# STM32G483VET6 register map
File version: 1.0
Registers are 32-bit, access not given, reset 0x0 unless marked. A register's access mark holds for its fields unless they carry their own. Offsets are from the block's base; [hi:lo] are bit positions; {n}, {i} and the like mark numbered series.

## DMAMUX1
Base 0x40020800
0x00 CCR0
0x04 CCR1
0x08 CCR2
0x0C CCR3
0x10 CCR4
0x14 CCR5
{0x0+4i} CCR{i} (i=6..9)
0x28 CCR0
0x2C CCR1
0x30 CCR2
0x34 CCR3
0x38 CCR4
0x3C CCR5
0x80 CCRs
0x100 CCR0
0x104 CCR1
0x108 CCR2
0x10C CCR3
0x140 CCRs

## CORDIC
Base 0x40020C00
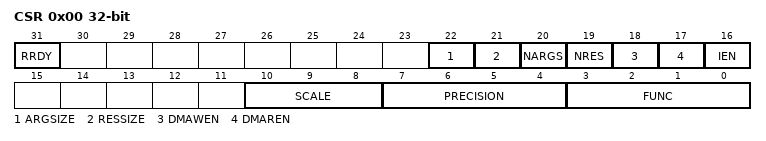
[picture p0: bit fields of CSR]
0x00 CSR
  [31] RRDY, [22] ARGSIZE, [21] RESSIZE, [20] NARGS, [19] NRES, [18] DMAWEN, [17] DMAREN, [16] IEN, [10:8] SCALE, [7:4] PRECISION, [3:0] FUNC
0x04 WDATA
  [31:0] ARG
0x08 RDATA
  [31:0] RES

## FMAC
Base 0x40021400
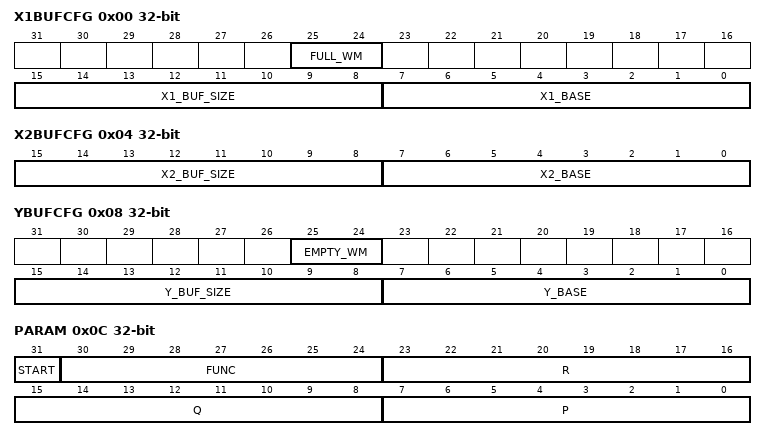
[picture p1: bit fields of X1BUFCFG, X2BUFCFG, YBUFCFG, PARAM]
0x00 X1BUFCFG
  [25:24] FULL_WM, [15:8] X1_BUF_SIZE, [7:0] X1_BASE
0x04 X2BUFCFG
  [15:8] X2_BUF_SIZE, [7:0] X2_BASE
0x08 YBUFCFG
  [25:24] EMPTY_WM, [15:8] Y_BUF_SIZE, [7:0] Y_BASE
0x0C PARAM
  [31] START, [30:24] FUNC, [23:16] R, [15:8] Q, [7:0] P
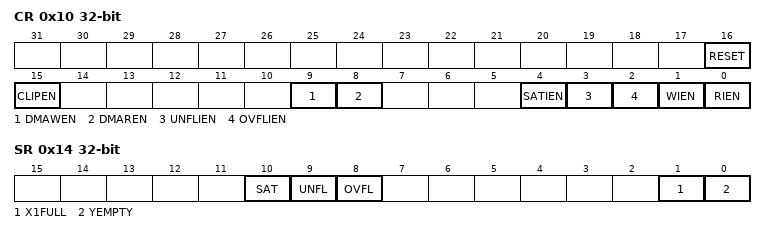
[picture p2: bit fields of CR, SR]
0x10 CR
  [16] RESET, [15] CLIPEN, [9] DMAWEN, [8] DMAREN, [4] SATIEN, [3] UNFLIEN, [2] OVFLIEN, [1] WIEN, [0] RIEN
0x14 SR
  [10] SAT, [9] UNFL, [8] OVFL, [1] X1FULL, [0] YEMPTY
0x18 WDATA
  [15:0] WDATA
0x1C RDATA
  [15:0] RDATA

## FLASH
Base 0x40022000
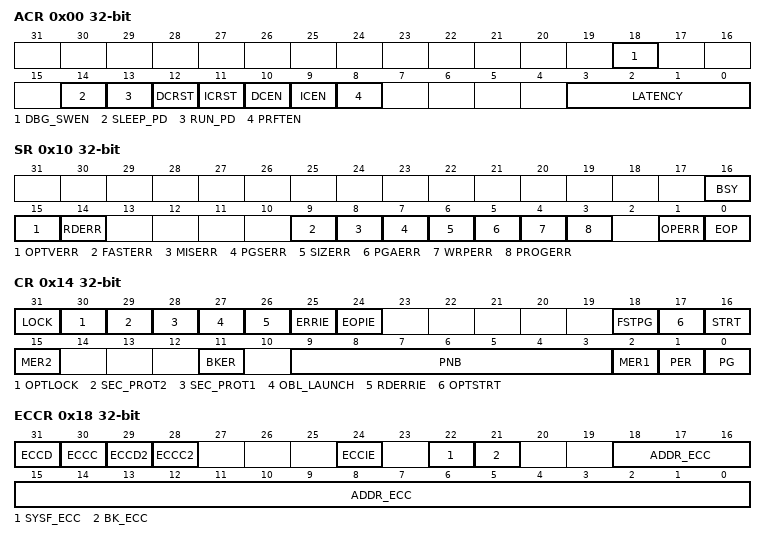
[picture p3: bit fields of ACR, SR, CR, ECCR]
0x00 ACR
  [18] DBG_SWEN, [14] SLEEP_PD, [13] RUN_PD, [12] DCRST, [11] ICRST, [10] DCEN, [9] ICEN, [8] PRFTEN, [3:0] LATENCY
0x04 PDKEYR
0x08 KEYR
0x0C OPTKEYR
0x10 SR
  [16] BSY, [15] OPTVERR, [14] RDERR, [9] FASTERR, [8] MISERR, [7] PGSERR, [6] SIZERR, [5] PGAERR, [4] WRPERR, [3] PROGERR, [1] OPERR, [0] EOP
0x14 CR
  [31] LOCK, [30] OPTLOCK, [29] SEC_PROT2, [28] SEC_PROT1, [27] OBL_LAUNCH, [26] RDERRIE, [25] ERRIE, [24] EOPIE, [18] FSTPG, [17] OPTSTRT, [16] STRT, [15] MER2, [11] BKER, [9:3] PNB, [2] MER1, [1] PER, [0] PG
0x18 ECCR
  [31] ECCD, [30] ECCC, [29] ECCD2, [28] ECCC2, [24] ECCIE, [22] SYSF_ECC, [21] BK_ECC, [18:0] ADDR_ECC
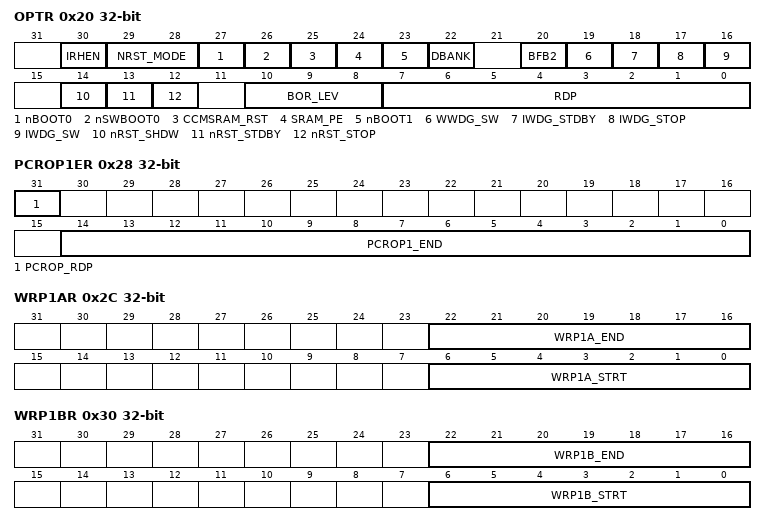
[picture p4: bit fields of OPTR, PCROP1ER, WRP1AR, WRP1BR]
0x20 OPTR
  [30] IRHEN, [29:28] NRST_MODE, [27] nBOOT0, [26] nSWBOOT0, [25] CCMSRAM_RST, [24] SRAM_PE, [23] nBOOT1, [22] DBANK, [20] BFB2, [19] WWDG_SW, [18] IWDG_STDBY, [17] IWDG_STOP, [16] IWDG_SW, [14] nRST_SHDW, [13] nRST_STDBY, [12] nRST_STOP, [10:8] BOR_LEV, [7:0] RDP
0x24 PCROP1SR
  [14:0] PCROP1_STRT
0x28 PCROP1ER
  [31] PCROP_RDP, [14:0] PCROP1_END
0x2C WRP1AR
  [22:16] WRP1A_END, [6:0] WRP1A_STRT
0x30 WRP1BR
  [22:16] WRP1B_END, [6:0] WRP1B_STRT
0x44 PCROP2SR
  [14:0] PCROP2_STRT
0x48 PCROP2ER
  [14:0] PCROP2_END
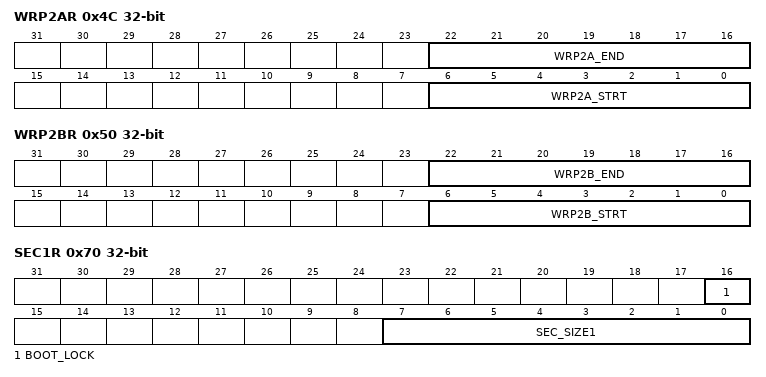
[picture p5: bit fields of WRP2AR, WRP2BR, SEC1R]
0x4C WRP2AR
  [22:16] WRP2A_END, [6:0] WRP2A_STRT
0x50 WRP2BR
  [22:16] WRP2B_END, [6:0] WRP2B_STRT
0x70 SEC1R
  [16] BOOT_LOCK, [7:0] SEC_SIZE1
0x74 SEC2R
  [7:0] SEC_SIZE2

## CRC
Base 0x40023000
0x00 DR
0x04 IDR
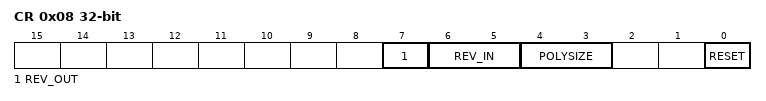
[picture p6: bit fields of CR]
0x08 CR
  [7] REV_OUT, [6:5] REV_IN, [4:3] POLYSIZE, [0] RESET
0x10 INIT
0x14 POL

## GPIOA
Base 0x48000000
Same registers: GPIOB 0x48000400, GPIOC 0x48000800, GPIOD 0x48000C00, GPIOE 0x48001000, GPIOF 0x48001400, GPIOG 0x48001800
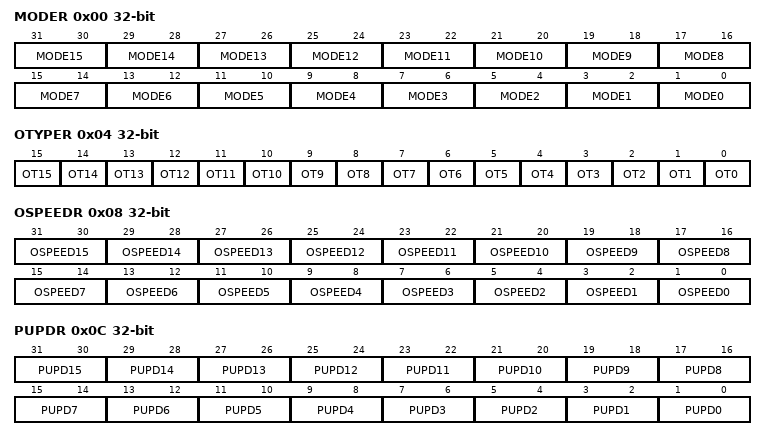
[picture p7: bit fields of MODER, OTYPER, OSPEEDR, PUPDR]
0x00 MODER
  [2n+1:2n] MODE{n} (n=0..15)
0x04 OTYPER
  [n] OT{n} (n=0..15)
0x08 OSPEEDR
  [2n+1:2n] OSPEED{n} (n=0..15)
0x0C PUPDR
  [2n+1:2n] PUPD{n} (n=0..15)
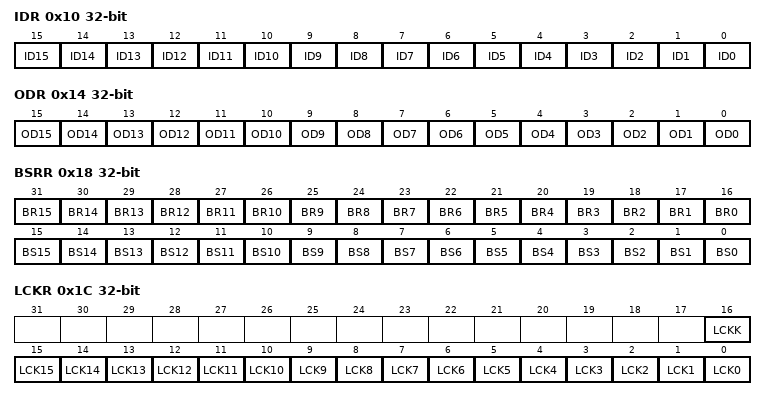
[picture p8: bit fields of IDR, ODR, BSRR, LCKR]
0x10 IDR
  [n] ID{n} (n=0..15)
0x14 ODR
  [n] OD{n} (n=0..15)
0x18 BSRR
  [n+16] BR{n} (n=0..15), [n] BS{n} (n=0..15)
0x1C LCKR
  [16] LCKK, [n] LCK{n} (n=0..15)
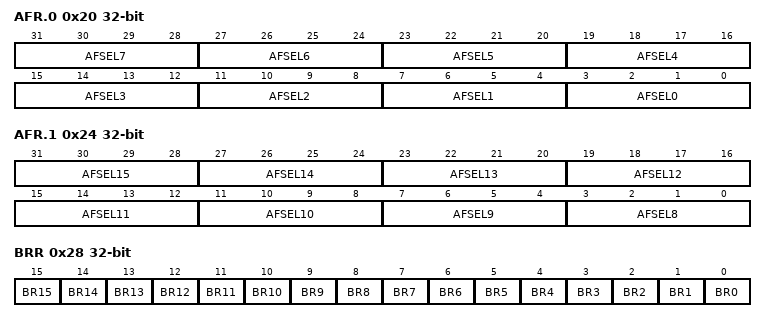
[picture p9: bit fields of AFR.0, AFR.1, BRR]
0x20 AFR.0
  [4n+3:4n] AFSEL{n} (n=0..7)
0x24 AFR.1
  [4n-29:4n-32] AFSEL{n} (n=8..15)
0x28 BRR
  [n] BR{n} (n=0..15)

## ADC1
Base 0x50000000
Same registers: ADC2 0x50000100, ADC3 0x50000400, ADC4 0x50000500, ADC5 0x50000600
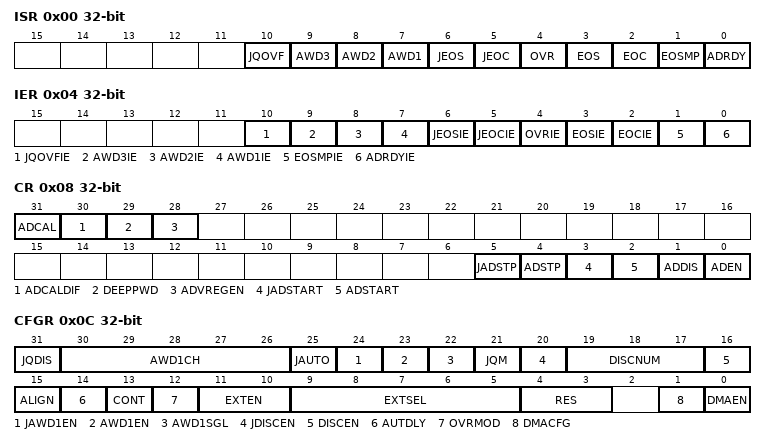
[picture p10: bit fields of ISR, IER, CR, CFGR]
0x00 ISR
  [10] JQOVF, [9] AWD3, [8] AWD2, [7] AWD1, [6] JEOS, [5] JEOC, [4] OVR, [3] EOS, [2] EOC, [1] EOSMP, [0] ADRDY
0x04 IER
  [10] JQOVFIE, [9] AWD3IE, [8] AWD2IE, [7] AWD1IE, [6] JEOSIE, [5] JEOCIE, [4] OVRIE, [3] EOSIE, [2] EOCIE, [1] EOSMPIE, [0] ADRDYIE
0x08 CR
  [31] ADCAL, [30] ADCALDIF, [29] DEEPPWD, [28] ADVREGEN, [5] JADSTP, [4] ADSTP, [3] JADSTART, [2] ADSTART, [1] ADDIS, [0] ADEN
0x0C CFGR
  [31] JQDIS, [30:26] AWD1CH, [25] JAUTO, [24] JAWD1EN, [23] AWD1EN, [22] AWD1SGL, [21] JQM, [20] JDISCEN, [19:17] DISCNUM, [16] DISCEN, [15] ALIGN, [14] AUTDLY, [13] CONT, [12] OVRMOD, [11:10] EXTEN, [9:5] EXTSEL, [4:3] RES, [1] DMACFG, [0] DMAEN
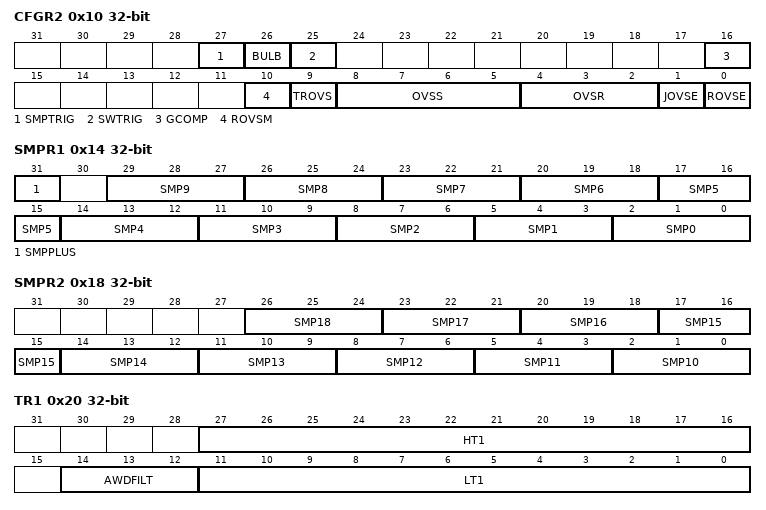
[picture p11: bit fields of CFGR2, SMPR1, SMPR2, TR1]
0x10 CFGR2
  [27] SMPTRIG, [26] BULB, [25] SWTRIG, [16] GCOMP, [10] ROVSM, [9] TROVS, [8:5] OVSS, [4:2] OVSR, [1] JOVSE, [0] ROVSE
0x14 SMPR1
  [31] SMPPLUS, [3n+2:3n] SMP{n} (n=0..9)
0x18 SMPR2
  [3n-28:3n-30] SMP{n} (n=10..18)
0x20 TR1
  [27:16] HT1, [14:12] AWDFILT, [11:0] LT1
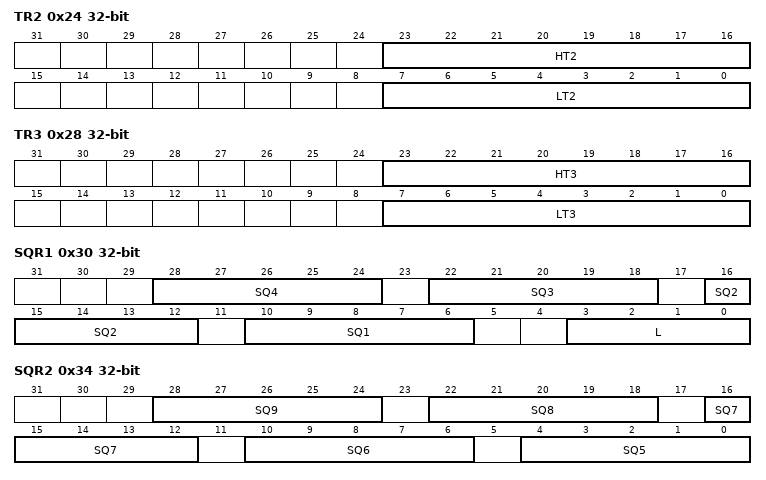
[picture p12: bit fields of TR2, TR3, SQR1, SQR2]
0x24 TR2
  [23:16] HT2, [7:0] LT2
0x28 TR3
  [23:16] HT3, [7:0] LT3
0x30 SQR1
  [6n+4:6n] SQ{n} (n=1..4), [3:0] L
0x34 SQR2
  [6n-26:6n-30] SQ{n} (n=5..9)
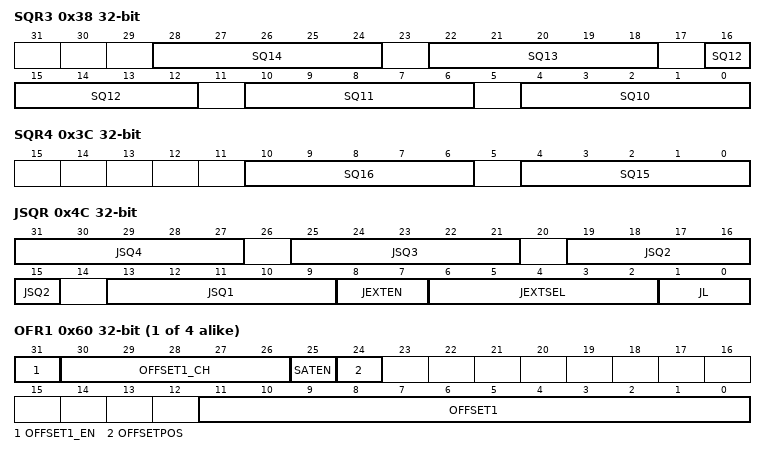
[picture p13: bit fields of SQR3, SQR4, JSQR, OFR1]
0x38 SQR3
  [6n-56:6n-60] SQ{n} (n=10..14)
0x3C SQR4
  [10:6] SQ16, [4:0] SQ15
0x40 DR
  [15:0] RDATA
0x4C JSQR
  [6n+7:6n+3] JSQ{n} (n=1..4), [8:7] JEXTEN, [6:2] JEXTSEL, [1:0] JL
{0x5C+4i} OFR{i} (i=1..4)
  [31] OFFSET{i}_EN, [30:26] OFFSET{i}_CH, [25] SATEN, [24] OFFSETPOS, [11:0] OFFSET{i}
{0x7C+4i} JDR{i} (i=1..4)
  [15:0] JDATA
0xA0 AWD2CR
  [18:0] AWD2CH
0xA4 AWD3CR
  [18:0] AWD3CH
0xB0 DIFSEL
  [18:0] DIFSEL
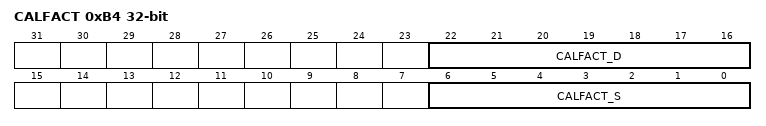
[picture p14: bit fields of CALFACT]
0xB4 CALFACT
  [22:16] CALFACT_D, [6:0] CALFACT_S
0xC0 GCOMP
  [13:0] GCOMPCOEFF
